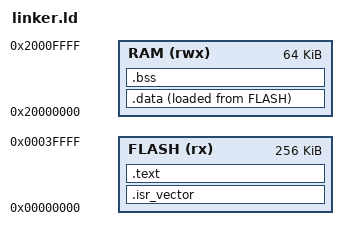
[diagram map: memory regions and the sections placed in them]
MEMORY
{
    FLASH (rx)  : ORIGIN = 0x00000000, LENGTH = 256K
    RAM   (rwx) : ORIGIN = 0x20000000, LENGTH = 64K
}

_stack_top = ORIGIN(RAM) + LENGTH(RAM);

SECTIONS
{
    .isr_vector :
    {
        KEEP(*(.isr_vector))
    } > FLASH

    .text :
    {
        *(.text*)
        *(.rodata*)
    } > FLASH

    _data_load = LOADADDR(.data);

    .data :
    {
        _data_start = .;
        *(.data*)
        _data_end = .;
    } > RAM AT > FLASH

    .bss :
    {
        _bss_start = .;
        *(.bss*)
        *(COMMON)
        _bss_end = .;
    } > RAM
}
